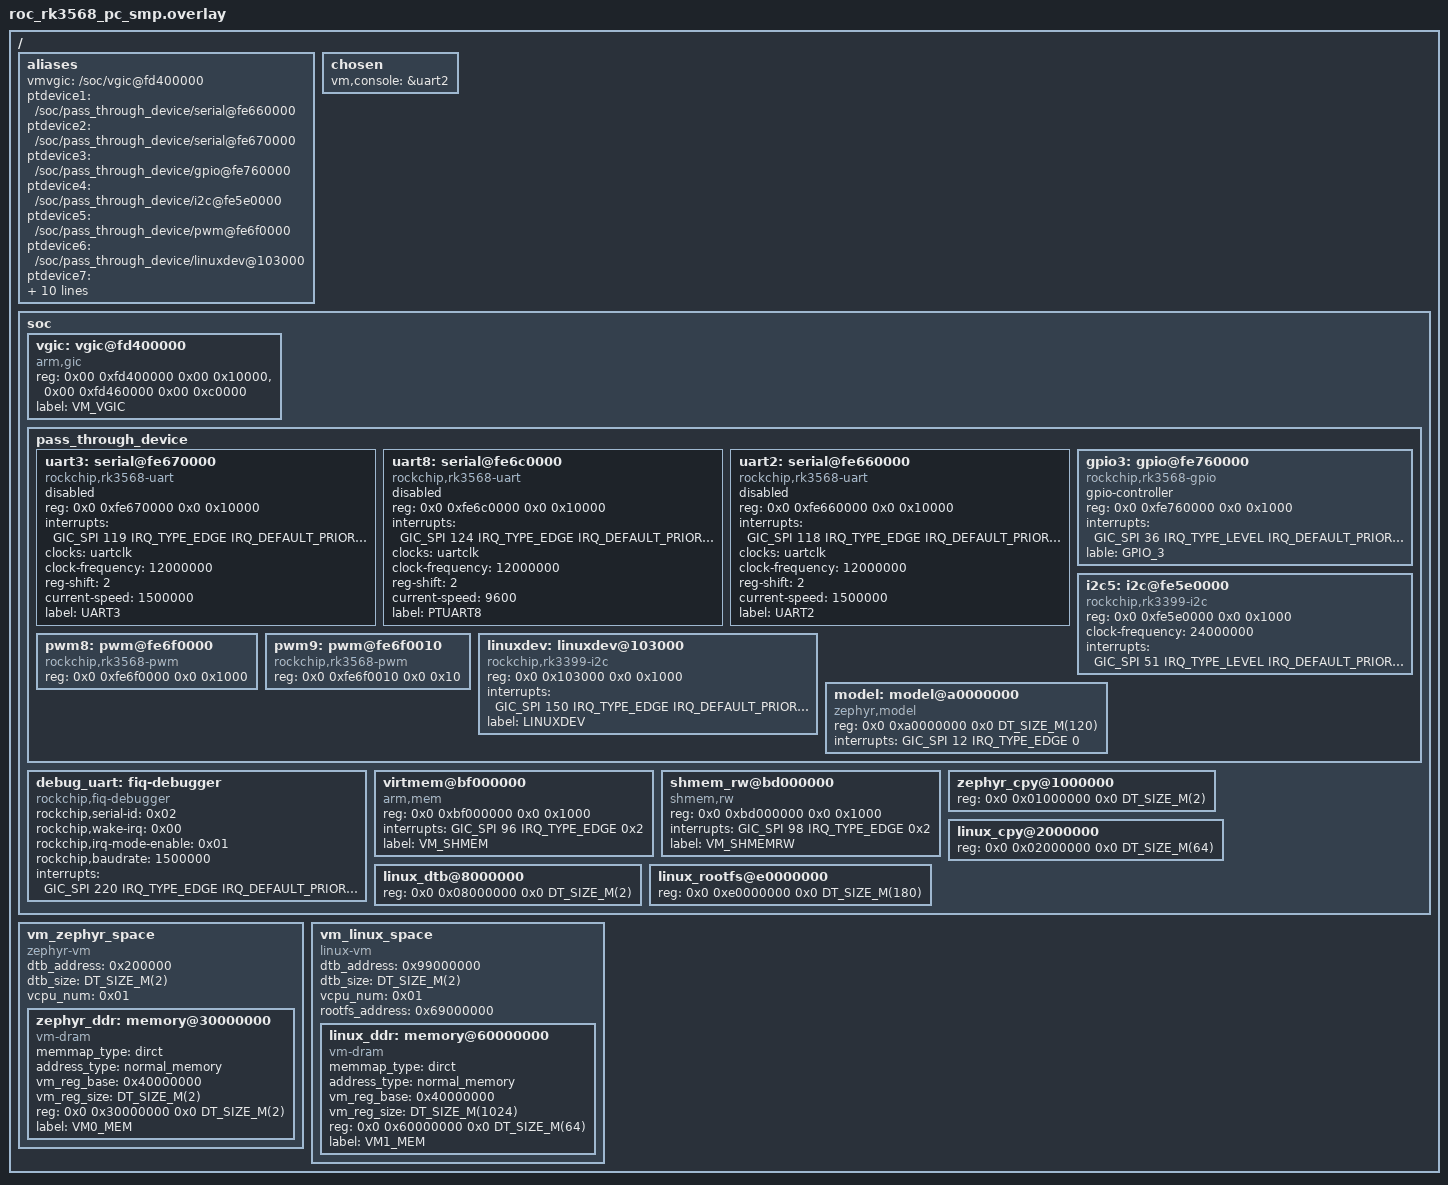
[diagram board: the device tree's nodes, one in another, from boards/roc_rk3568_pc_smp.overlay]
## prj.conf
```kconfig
# Project configuration
# Copyright 2021-2022 HNU-ESNL

# ZVM
CONFIG_ZVM=y
CONFIG_NO_OPTIMIZATIONS=y
# CONFIG_ZVM_ELF_LOADER=y
# Shell
CONFIG_SHELL=y
CONFIG_SHELL_GETOPT=y
CONFIG_SHELL_THREAD_PRIORITY_OVERRIDE=y
CONFIG_SHELL_THREAD_PRIORITY=4
CONFIG_SHELL_PROMPT_UART="zvm_host:~#"

# if CONFIG_SHELL is n, must set CONFIG_GETOPT to y
CONFIG_GETOPT=y
# if CONFIG_SHELL is n, must set CONFIG_THREAD_NAME to y
CONFIG_THREAD_NAME=y

#CPU MASK, this feature work only `CONFIG_SCHED_DUMB` is the selected
CONFIG_SCHED_CPU_MASK=y
CONFIG_SCHED_CPU_MASK_PIN_ONLY=y

# vm and vcpu configure
CONFIG_MAX_VM_NUM=2
CONFIG_MAX_VCPU_PER_VM=2

# C minimal lib
CONFIG_MINIMAL_LIBC_RAND=y
CONFIG_MINIMAL_LIBC_MALLOC_ARENA_SIZE=4096

# Enable Console
CONFIG_CONSOLE=y
CONFIG_CONSOLE_SUBSYS=y
CONFIG_CONSOLE_GETLINE=y
CONFIG_UART_CONSOLE=y

# If disable, system will always be interrupted by
# periodic shell timeout.
# CONFIG_SHELL_BACKEND_SERIAL_INTERRUPT_DRIVEN=n

# disable log_sys default
CONFIG_LOG=y
CONFIG_LOG_MODE_MINIMAL=y
#Enable __ASSERT() macro
CONFIG_ASSERT=y

#zvm log info system
CONFIG_ZVM_DEBUG_LOG_INFO=y

#zvm overall dtb file support
CONFIG_ZVM_OVERALL_DTB_FILE_SUPPORT=n

# ZVM Max PREEMPT_PRIORITIES
CONFIG_NUM_PREEMPT_PRIORITIES=15

# timer
CONFIG_TIMING_FUNCTIONS=y
CONFIG_SCHED_DEADLINE=y

CONFIG_THREAD_STACK_INFO=y
CONFIG_KOBJECT_TEXT_AREA=4096
CONFIG_MAIN_STACK_SIZE=32768
CONFIG_IDLE_STACK_SIZE=65536
CONFIG_ISR_STACK_SIZE=81920
CONFIG_SHELL_STACK_SIZE=65536

# 128MB heap size.
CONFIG_HEAP_MEM_POOL_SIZE=1073741824

# expand partitions
CONFIG_MAX_DOMAIN_PARTITIONS=32

# MAX table
CONFIG_MAX_XLAT_TABLES=20480

# dynamic memory allocation
CONFIG_VM_DYNAMIC_MEMORY=y

# dtb file support
CONFIG_VM_DTB_FILE_INPUT=y

# image name
CONFIG_KERNEL_BIN_NAME="zvm_host"

# https://docs.zephyrproject.org/latest/kconfig.html#CONFIG_DISK_DRIVER_RAM
CONFIG_DISK_ACCESS=y
CONFIG_DISK_DRIVERS=y
CONFIG_DISK_DRIVER_RAM=y
CONFIG_DISK_RAM_VOLUME_SIZE=192

#LIBC SUPPORT
CONFIG_MINIMAL_LIBC_RAND=y

CONFIG_DYNAMIC_INTERRUPTS=y

CONFIG_NO_OPTIMIZATIONS=y
```

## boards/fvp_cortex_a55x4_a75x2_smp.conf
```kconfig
# Project configuration
# Copyright 2022-2023 HNU-ESNL

#ARMV8 NO-SECURE MODE
CONFIG_ARMV8_A_NS=y

# kernel vm size(16M virt ram start + size)
# It is the virt size of kernel, must bigger than true kernel size.
CONFIG_KERNEL_VM_SIZE=0x40000000

# uart
CONFIG_UART_PL011_PORT1=n

# vgic device.
CONFIG_VM_VGICV3=y

# vuart device.
CONFIG_VM_SERIAL1=y
CONFIG_VM_SERIAL2=y

# make more table for vm's pgd
CONFIG_ZVM_ZEPHYR_MAX_XLAT_TABLES=512
CONFIG_ZVM_LINUX_MAX_XLAT_TABLES=10240

# enable vm device below:
CONFIG_VM_VIRTIO_MMIO=y
CONFIG_VM_VIRTIO_BLOCK=y
CONFIG_MEM_INIT_PRIORITY=59
CONFIG_MEMRW_INIT_PRIORITY=60
```

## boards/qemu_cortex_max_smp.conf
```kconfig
# Project configuration
# Copyright 2021-2022 HNU

#ARMV8 NO-SECURE MODE
CONFIG_ARMV8_A_NS=y

# kernel vm size(16M virt ram start + size)
# It is the virt size of kernel, must bigger than true kernel size.
CONFIG_KERNEL_VM_SIZE=0xa0000000

# uart
CONFIG_UART_PL011_PORT1=n

# pci controller
CONFIG_PCIE=y
CONFIG_PCIE_CONTROLLER=y
CONFIG_PCIE_ECAM=y

# vgic device.
CONFIG_VM_VGICV3=y

# vuart device.
CONFIG_VM_SERIAL1=y
CONFIG_VM_SERIAL2=y

# make more table for vm's pgd
CONFIG_ZVM_ZEPHYR_MAX_XLAT_TABLES=512
CONFIG_ZVM_LINUX_MAX_XLAT_TABLES=10240

# heap size of zephyr
# CONFIG_HEAP_MEM_POOL_SIZE=1610612736

# enable vm device below:
CONFIG_VM_VIRTIO_MMIO=y
CONFIG_VM_VIRTIO_BLOCK=y
CONFIG_VM_SHMEM=n
CONFIG_VM_SHMEMRW=n
CONFIG_MEM_INIT_PRIORITY=59
CONFIG_MEMRW_INIT_PRIORITY=60

# enable pci bus support
CONFIG_VM_PCI_BUS_CONTROLLER=y
CONFIG_VM_PCI_BUS_INIT_PRIORITY=68
```

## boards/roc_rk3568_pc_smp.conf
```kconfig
# Project configuration
# Copyright 2021-2022 HNU

#ARMV8 NO-SECURE MODE
CONFIG_ARMV8_A_NS=y

# kernel vm size(16M virt ram start + size)
# It is the virt size of kernel, must bigger than true kernel size.
# 1024 MB
CONFIG_KERNEL_VM_SIZE=0x40000000

# vgic device.
CONFIG_VM_VGICV3=y

# vuart device.
CONFIG_VM_SERIAL1=y
CONFIG_VM_SERIAL2=y

# syscon device
CONFIG_VM_SYSCON_CONTROLLER=y

# fiq debugger
CONFIG_VM_FIQ_DEBUGGER=y
CONFIG_VM_CLOCK_SYSTEM_CONTROLLER=y

# make more table for vm's pgd
CONFIG_ZVM_ZEPHYR_MAX_XLAT_TABLES=1024
CONFIG_ZVM_LINUX_MAX_XLAT_TABLES=10240

# CONFIG_VM_PCI_BUS_CONTROLLER=y
# CONFIG_VM_PCI_BUS_INIT_PRIORITY=68

CONFIG_VM_SHMEM=n
CONFIG_VM_SHMEMRW=n
CONFIG_MEM_INIT_PRIORITY=59
CONFIG_MEMRW_INIT_PRIORITY=60
```

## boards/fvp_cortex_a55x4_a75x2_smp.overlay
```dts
/*
 * Copyright 2021-2022 HNU-ESNL
 *
 * SPDX-License-Identifier: Apache-2.0
 */

/{

    aliases {
        vmvirtio1 = "/soc/virtio_mmio@1c130000";
        vmvirtio2 = "/soc/virtio_mmio@1c131000";
        linuxcpy = "/soc/linux_cpy@e0000000";
        linuxrfs = "/soc/linux_rootfs@e4000000";
        /*Passthrough device.*/
        ptdevice1 = "/soc/pass_through_device/uart@1c0a0000";
        ptdevice2 = "/soc/pass_through_device/uart@1c0b0000";
    };

    chosen {
        vm,console = &uart0;
    };

    soc {

        virtio_mmio@1c130000 {
            interrupts = <GIC_SPI 0x10 IRQ_TYPE_EDGE 0>;
            reg = <0x00 0x1c130000 0x00 0x1000>;
            compatible = "virtio,mmio";
            device_type = "virtio";
            virtio_type = <2>;
        };

        virtio_mmio@1c131000 {
            interrupts = <GIC_SPI 0x11 IRQ_TYPE_EDGE 0>;
            reg = <0x00 0x1c131000 0x00 0x1000>;
            compatible = "virtio,mmio";
            device_type = "virtio";
            virtio_type = <2>;
        };

        linux_cpy@e0000000 {
            reg = <0x0 0xe0000000 0x0 DT_SIZE_M(64)>;
        };

        linux_rootfs@e4000000 {
            reg = <0x0 0xe4000000 0x0 DT_SIZE_M(180)>;
        };

        pass_through_device {
            #address-cells = <2>;
            #size-cells = <2>;
            ranges;

            uart1: uart@1c0a0000 {

                compatible = "arm,pl011";
                reg = <0x0 0x1c0a0000 0x0 0x1000>;
                status = "disabled";
                interrupts = <GIC_SPI 6 0 IRQ_TYPE_LEVEL>; //<SECOND PARA IS OFFSET>
                interrupt-names = "irq_0";
                label = "UART_1";
                clocks = <&uartclk>;
            };

            uart2: uart@1c0b0000 {

                compatible = "arm,pl011";
                reg = <0x0 0x1c0b0000 0x0 0x1000>;
                status = "disabled";
                interrupts = <GIC_SPI 7 0 IRQ_TYPE_LEVEL>; //<SECOND PARA IS OFFSET>
                interrupt-names = "irq_0";
                label = "UART_2";
                clocks = <&uartclk>;
            };

        };

    };

    vm_zephyr_space {
        #address-cells = <2>;
        #size-cells = <2>;
        compatible = "zephyr-vm";
        dtb_address = <0xa9000000>;
        dtb_size = <DT_SIZE_M(2)>;
        vcpu_num = <0x01>;

        zephyr_ddr: memory@a0000000 {
            compatible = "vm-dram";
            memmap_type = "dirct";
            address_type = "normal_memory";
            vm_reg_base = <0x88000000>;
            vm_reg_size = <DT_SIZE_M(2)>;
            reg = <0x0 0xa0000000 0x0 DT_SIZE_M(2)>;
            label = "VM0_MEM";
        };

    };

    vm_linux_space {
        #address-cells = <2>;
        #size-cells = <2>;
        compatible = "linux-vm";
        dtb_address = <0xc0000000>;
        dtb_size = <DT_SIZE_M(2)>;
        vcpu_num = <0x01>;
        rootfs_address = <0xf8000000>;

        linux_ddr: memory@b0000000 {
            compatible = "vm-dram";
            memmap_type = "dirct";
            address_type = "normal_memory";
            vm_reg_base = <0x80000000>;
            vm_reg_size = <DT_SIZE_M(1024)>;
            reg = <0x0 0xb0000000 0x0 DT_SIZE_M(1024)>;
            label = "VM1_MEM";
        };
    };

};

&uart1 {
	status = "okay";
	current-speed = <115200>;
};

&uart2 {
	status = "okay";
	current-speed = <115200>;
};
```

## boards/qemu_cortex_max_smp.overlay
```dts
/*
 * Copyright 2021-2022 HNU
 *
 * SPDX-License-Identifier: Apache-2.0
 */

/{
	aliases {
        vmvirtio1 = "/soc/virtio_mmio@a000000";
        vmvirtio2 = "/soc/virtio_mmio@a001000";
        zephyrcpy = "/soc/zephyr_cpy@a0000000";
        linuxcpy = "/soc/linux_cpy@a2000000";
        linuxrfs = "/soc/linux_rootfs@aa000000";
        linuxdtb = "/soc/linux_dtb@a8000000";
        /*Passthrough device.*/
		ptdevice1 = "/soc/pass_through_device/uart@9001000";
		ptdevice2 = "/soc/pass_through_device/uart@9002000";
	};

    chosen {
		vm,console = &uart0;
        zephyr_pcie_controller = "/soc/pcie@4010000000";
	};

    soc {

        virtio_mmio@a000000 {
            interrupts = <GIC_SPI 0x10 IRQ_TYPE_EDGE 0>;
            reg = <0x00 0xa000000 0x00 0x1000>;
            compatible = "virtio,mmio";
            device_type = "virtio";
            virtio_type = <2>;
        };

        virtio_mmio@a001000 {
            interrupts = <GIC_SPI 0x11 IRQ_TYPE_EDGE 0>;
            reg = <0x00 0xa001000 0x00 0x1000>;
            compatible = "virtio,mmio";
            device_type = "virtio";
            virtio_type = <2>;
        };

        pcie@4010000000 {
            compatible = "pci-host-ecam-generic";
            interrupt-map-mask = <0x1800 0x00 0x00 0x07>;
            interrupt-map = <0x00 0x00 0x00 0x01 0x8005 0x00 0x00 0x00 0x03 0x04
                            0x00 0x00 0x00 0x02 0x8005 0x00 0x00 0x00 0x04 0x04
                            0x00 0x00 0x00 0x03 0x8005 0x00 0x00 0x00 0x05 0x04
                            0x00 0x00 0x00 0x04 0x8005 0x00 0x00 0x00 0x06 0x04
                            0x800 0x00 0x00 0x01 0x8005 0x00 0x00 0x00 0x04 0x04
                            0x800 0x00 0x00 0x02 0x8005 0x00 0x00 0x00 0x05 0x04
                            0x800 0x00 0x00 0x03 0x8005 0x00 0x00 0x00 0x06 0x04
                            0x800 0x00 0x00 0x04 0x8005 0x00 0x00 0x00 0x03 0x04
                            0x1000 0x00 0x00 0x01 0x8005 0x00 0x00 0x00 0x05 0x04
                            0x1000 0x00 0x00 0x02 0x8005 0x00 0x00 0x00 0x06 0x04
                            0x1000 0x00 0x00 0x03 0x8005 0x00 0x00 0x00 0x03 0x04
                            0x1000 0x00 0x00 0x04 0x8005 0x00 0x00 0x00 0x04 0x04
                            0x1800 0x00 0x00 0x01 0x8005 0x00 0x00 0x00 0x06 0x04
                            0x1800 0x00 0x00 0x02 0x8005 0x00 0x00 0x00 0x03 0x04
                            0x1800 0x00 0x00 0x03 0x8005 0x00 0x00 0x00 0x04 0x04
                            0x1800 0x00 0x00 0x04 0x8005 0x00 0x00 0x00 0x05 0x04>;
            #interrupt-cells = <0x01>;
            ranges = <0x1000000 0x00 0x00 0x00 0x3eff0000 0x00 0x10000>,
                    <0x2000000 0x00 0x10000000 0x00 0x10000000 0x00 0x10000000>,
                    <0x3000000 0x00 0x20000000 0x00 0x20000000 0x00 0x1eff0000>;
            reg = <0x40 0x10000000 0x00 0x10000000>;
            msi-parent = <&gic_ist>;
            bus-range = <0x00 0xff>;
            #size-cells = <0x02>;
            #address-cells = <0x03>;
            device_type = "pci";
            compatible = "pci-host-ecam-generic";
        };

        zephyr_cpy@a0000000 {
            reg = <0x0 0xa0000000 0x0 DT_SIZE_M(2)>;
        };

        linux_cpy@a2000000 {
            reg = <0x0 0xa2000000 0x0 DT_SIZE_M(64)>;
        };

        linux_dtb@a8000000 {
            reg = <0x0 0xa8000000 0x0 DT_SIZE_M(2)>;
        };

        linux_rootfs@aa000000 {
            reg = <0x0 0xaa000000 0x0 DT_SIZE_M(180)>;
        };

        pass_through_device {

            #address-cells = <2>;
            #size-cells = <2>;
            ranges;

            uart1: uart@9001000 {
                compatible = "arm,pl011";
                reg = <0x00 0x09001000 0x00 0x1000>;
                interrupts = <GIC_SPI 10 IRQ_TYPE_EDGE 0>;
                interrupt-names = "irq_0";
                clocks = <&uartclk>;
                status = "reserved";
                current-speed = <115200>;
                label = "UART_1";
            };

            uart2: uart@9002000 {
                compatible = "arm,pl011";
                reg = <0x00 0x09002000 0x00 0x1000>;
                interrupts = <GIC_SPI 11 IRQ_TYPE_EDGE 0>;
                interrupt-names = "irq_0";
                clocks = <&uartclk>;
                status = "reserved";
                current-speed = <115200>;
                label = "UART_2";
            };

        };

    };

    vm_zephyr_space {
        #address-cells = <2>;
        #size-cells = <2>;
        compatible = "zephyr-vm";
        dtb_address = <0x00000000>;
        dtb_size = <DT_SIZE_M(2)>;
        vcpu_num = <0x01>;

        zephyr_ddr: memory@80000000 {
            compatible = "vm-dram";
            memmap_type = "direct";
            address_type = "normal_memory";
            vm_reg_base = <0x40000000>;
            vm_reg_size = <DT_SIZE_M(2)>;
            reg = <0x0 0x80000000 0x0 DT_SIZE_M(1)>;
            label = "VM0_MEM";
        };
    };

    vm_linux_space {
        #address-cells = <2>;
        #size-cells = <2>;
        compatible = "linux-vm";
        dtb_address = <0xf2000000>;
        dtb_size = <DT_SIZE_M(2)>;
        vcpu_num = <0x01>;
        rootfs_address = <0xc9000000>;

        linux_ddr: memory@c0000000 {
            compatible = "vm-dram";
            memmap_type = "direct";
            address_type = "normal_memory";
            vm_reg_base = <0x40000000>;
            vm_reg_size = <DT_SIZE_M(1024)>;
            reg = <0x0 0xc0000000 0x0 DT_SIZE_M(64)>;
            label = "VM1_MEM";
        };

        /* Define a pci device instance for vm. */
        linux_ivshmem {
            compatible = "virtio,pci";
            /* ivshmem device */
            type = <0x03>;
            domain = <0x01>;
            bdf = <0x00>;
            /* little endian bar_mask */
            bar_mask0 = <0xfffff000>;
            bar_mask1 = <0x00000000>;
            bar_mask2 = <0x00000000>;
            bar_mask3 = <0x00000000>;
            bar_mask4 = <0x00000000>;
            bar_mask5 = <0x00000000>;
            shmem_region_start = <0x0>;
            shmem_dev_id = <0x0>;
            shmem_peers = <0x2>;
            shmem_protocol = <0x0>;
            status = "okay";
        };

    };
};
```

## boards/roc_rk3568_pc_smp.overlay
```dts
/*
 * Copyright 2021-2022 HNU-ESNL
 *
 * SPDX-License-Identifier: Apache-2.0
 */

/{
	aliases {
        vmvgic = "/soc/vgic@fd400000";
		ptdevice1 = "/soc/pass_through_device/serial@fe660000";
		ptdevice2 = "/soc/pass_through_device/serial@fe670000";
        ptdevice3 = "/soc/pass_through_device/gpio@fe760000";
        ptdevice4 = "/soc/pass_through_device/i2c@fe5e0000";
        ptdevice5 = "/soc/pass_through_device/pwm@fe6f0000";
        ptdevice6 = "/soc/pass_through_device/linuxdev@103000";
        ptdevice7 = "/soc/pass_through_device/serial@fe6c0000";
        ptdevice8 = "/soc/pass_through_device/model@a0000000";
        linuxdebugger = "/soc/fiq-debugger";
        vmvirtmem = "/soc/virtmem@bf000000";
        vmshmemrw = "/soc/shmem_rw@bd000000";
        zephyrcpy = "/soc/zephyr_cpy@1000000";
        linuxcpy = "/soc/linux_cpy@2000000";
        linuxdtb = "/soc/linux_dtb@8000000";
        linuxrfs = "/soc/linux_rootfs@e0000000";
	};

	chosen {
		vm,console = &uart2;
	};


    soc {

        vgic: vgic@fd400000 {
            compatible = "arm,gic";
            reg = <0x00 0xfd400000 0x00 0x10000>,
                    <0x00 0xfd460000 0x00 0xc0000>;
            label = "VM_VGIC";
        };

        pass_through_device {

            #address-cells = <2>;
            #size-cells = <2>;
            ranges;

            uart3: serial@fe670000 {
                compatible = "rockchip,rk3568-uart", "ns16550";
                reg = <0x0 0xfe670000 0x0 0x10000>;
                interrupts = <GIC_SPI 119 IRQ_TYPE_EDGE IRQ_DEFAULT_PRIORITY>;
                clocks = <&uartclk>;
                clock-frequency = <12000000>;
                reg-shift = <2>;
                status = "reserved";
                current-speed = <1500000>;
                label = "UART3";
            };

            uart8: serial@fe6c0000 {
                compatible = "rockchip,rk3568-uart", "ns16550";
                reg = <0x0 0xfe6c0000 0x0 0x10000>;
                interrupts = <GIC_SPI 124 IRQ_TYPE_EDGE IRQ_DEFAULT_PRIORITY>;
                clocks = <&uartclk>;
                clock-frequency = <12000000>;
                reg-shift = <2>;
                status = "reserved";
                current-speed = <9600>;
                label = "PTUART8";
            };

            uart2: serial@fe660000 {
                compatible = "rockchip,rk3568-uart", "ns16550";
                reg = <0x0 0xfe660000 0x0 0x10000>;
                interrupts = <GIC_SPI 118 IRQ_TYPE_EDGE IRQ_DEFAULT_PRIORITY>;
                clocks = <&uartclk>;
                clock-frequency = <12000000>;
                reg-shift = <2>;
                status = "reserved";
                current-speed = <1500000>;
                label = "UART2";
            };

            gpio3: gpio@fe760000 {
                compatible = "rockchip,rk3568-gpio";
                gpio-controller;
                #gpio-cells = < 0x2 >;
                reg = <0x0 0xfe760000 0x0 0x1000 >;
                interrupts = < GIC_SPI 36 IRQ_TYPE_LEVEL IRQ_DEFAULT_PRIORITY >;
                lable = "GPIO_3";
                status = "okay";
            };

            i2c5: i2c@fe5e0000 {
                compatible = "rockchip,rk3399-i2c";
                reg = <0x0 0xfe5e0000 0x0 0x1000>;
                clock-frequency = <24000000>;
                interrupts = <GIC_SPI 51 IRQ_TYPE_LEVEL IRQ_DEFAULT_PRIORITY>;
                status = "okay";
            };

            pwm8: pwm@fe6f0000 {
                compatible = "rockchip,rk3568-pwm";
                reg = <0x0 0xfe6f0000 0x0 0x1000>;
                #pwm-cells = <3>;
                status = "okay";
            };

            pwm9: pwm@fe6f0010 {
                compatible = "rockchip,rk3568-pwm";
                reg = <0x0 0xfe6f0010 0x0 0x10>;
                #pwm-cells = <3>;
                status = "okay";
            };

            linuxdev: linuxdev@103000 {
                compatible = "rockchip,rk3399-i2c";
                reg = <0x0 0x103000 0x0 0x1000>;
                interrupts = <GIC_SPI 150 IRQ_TYPE_EDGE IRQ_DEFAULT_PRIORITY>;
                status = "okay";
                label = "LINUXDEV";
            };

            model: model@a0000000 {
                compatible = "zephyr,model";
                reg = <0x0 0xa0000000 0x0 DT_SIZE_M(120)>;
                interrupts = <GIC_SPI 12 IRQ_TYPE_EDGE 0>;
                interrupt-names = "irq_0";
		    };

        };

        debug_uart: fiq-debugger {
            compatible = "rockchip,fiq-debugger";
            rockchip,serial-id = <0x02>;
            rockchip,wake-irq = <0x00>;
            rockchip,irq-mode-enable = <0x01>;
            rockchip,baudrate = <1500000>;
            interrupts = <GIC_SPI 220 IRQ_TYPE_EDGE IRQ_DEFAULT_PRIORITY>;
            status = "okay";
        };

        virtmem@bf000000 {
            compatible = "arm,mem";
            device_type = "memory";
            reg = <0x0 0xbf000000 0x0 0x1000>;
            interrupts = <GIC_SPI 96 IRQ_TYPE_EDGE 0x2>;
            label = "VM_SHMEM";
            status = "okay";
        };

        shmem_rw@bd000000 {
            compatible = "shmem,rw";
            device_type = "memory";
            reg = <0x0 0xbd000000 0x0 0x1000>;
            interrupts = <GIC_SPI 98 IRQ_TYPE_EDGE 0x2>;
            label = "VM_SHMEMRW";
            status = "okay";
        };

        zephyr_cpy@1000000 {
            reg = <0x0 0x01000000 0x0 DT_SIZE_M(2)>;
        };

        linux_cpy@2000000 {
            reg = <0x0 0x02000000 0x0 DT_SIZE_M(64)>;
        };

        linux_dtb@8000000 {
            reg = <0x0 0x08000000 0x0 DT_SIZE_M(2)>;
        };

        linux_rootfs@e0000000 {
            reg = <0x0 0xe0000000 0x0 DT_SIZE_M(180)>;
        };
    };

    /*TODO: The device that used by vm will be added below. */
    vm_zephyr_space {
        #address-cells = <2>;
        #size-cells = <2>;
        compatible = "zephyr-vm";
        dtb_address = <0x200000>;
        dtb_size = <DT_SIZE_M(2)>;
        vcpu_num = <0x01>;

        zephyr_ddr: memory@30000000 {
            compatible = "vm-dram";
            memmap_type = "dirct";
            address_type = "normal_memory";
            vm_reg_base = <0x40000000>;
            vm_reg_size = <DT_SIZE_M(2)>;
            reg = <0x0 0x30000000 0x0 DT_SIZE_M(2)>;
            label = "VM0_MEM";
        };

    };

    vm_linux_space {
        #address-cells = <2>;
        #size-cells = <2>;
        compatible = "linux-vm";
        dtb_address = <0x99000000>;
        dtb_size = <DT_SIZE_M(2)>;
        vcpu_num = <0x01>;
        rootfs_address = <0x69000000>;

        linux_ddr: memory@60000000 {
            compatible = "vm-dram";
            memmap_type = "dirct";
            address_type = "normal_memory";
            vm_reg_base = <0x40000000>;
            vm_reg_size = <DT_SIZE_M(1024)>;
            reg = <0x0 0x60000000 0x0 DT_SIZE_M(64)>;
            label = "VM1_MEM";
        };
    };

};
```

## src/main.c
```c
/*
 * Copyright 2021-2022 HNU-ESNL
 *
 * SPDX-License-Identifier: Apache-2.0
 */

#include <zephyr.h>
#include <kernel.h>
#include <sys/printk.h>
#include <sys/mem_manage.h>
#include <shell/shell.h>
#include <shell/shell_uart.h>
#include <drivers/uart.h>
#include <kernel/thread.h>
#include <timing/timing.h>
#include <sys/time_units.h>

static void zvm_print_log(void)
{
	printk("\n");
	printk("\n");
	printk("█████████╗    ██╗     ██╗    ███╗    ███╗  \n");
	printk("╚════███╔╝    ██║     ██║    ████╗  ████║  \n");
	printk("   ███╔╝      ╚██╗   ██╔╝    ██╔ ████╔██║  \n");
	printk("  ██╔╝         ╚██  ██╔╝     ██║ ╚██╔╝██║  \n");
	printk("█████████╗      ╚████╔╝      ██║  ╚═╝ ██║  \n");
	printk("╚════════╝        ╚═╝        ╚═╝      ╚═╝  \n");

}

int main(int argc, char **argv)
{
	zvm_print_log();
	return 0;
}
```
